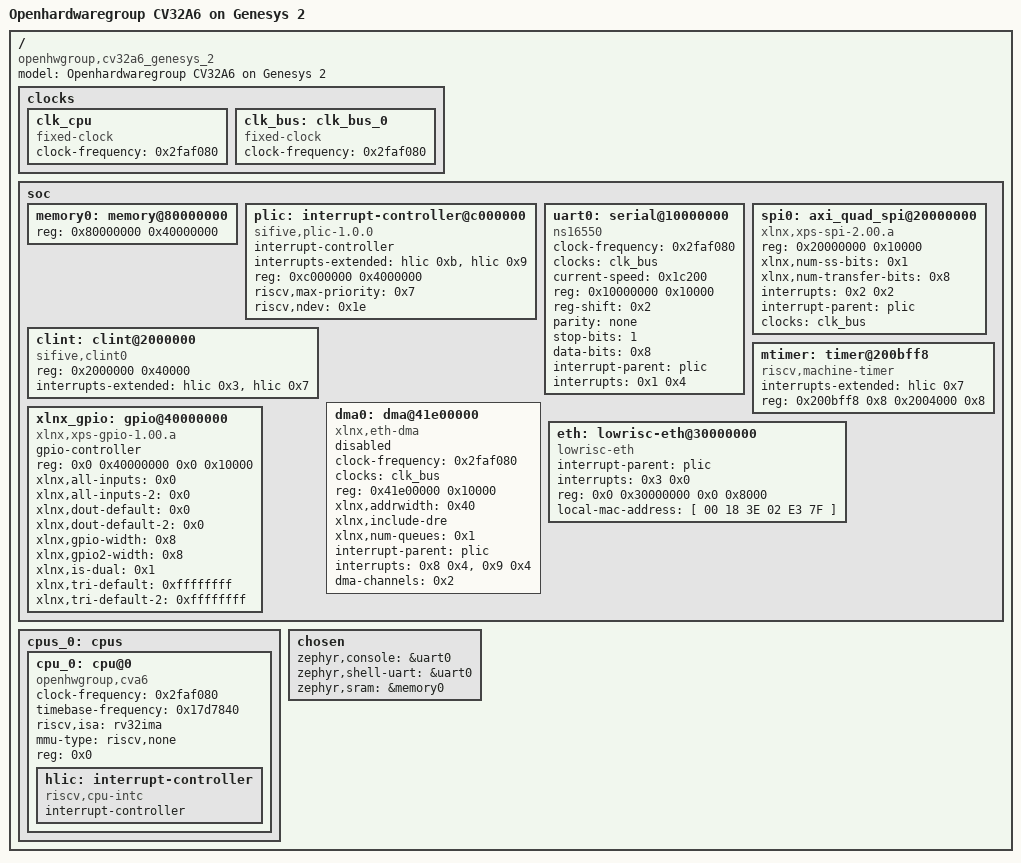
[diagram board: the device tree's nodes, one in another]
/dts-v1/;

/* node '/' defined in zephyr/dts/riscv/openhwgroup/cva6.dtsi:11 */
/ {
	#address-cells = < 0x1 >;                        /* in zephyr/dts/riscv/openhwgroup/cva6.dtsi:12 */
	#size-cells = < 0x1 >;                           /* in zephyr/dts/riscv/openhwgroup/cva6.dtsi:13 */
	model = "Openhardwaregroup CV32A6 on Genesys 2"; /* in zephyr/boards/openhwgroup/cv32a6_genesys_2/cv32a6_genesys_2.dts:11 */
	compatible = "openhwgroup,cv32a6_genesys_2";     /* in zephyr/boards/openhwgroup/cv32a6_genesys_2/cv32a6_genesys_2.dts:12 */

	/* node '/clocks' defined in zephyr/dts/riscv/openhwgroup/cva6.dtsi:15 */
	clocks {

		/* node '/clocks/clk_cpu' defined in zephyr/dts/riscv/openhwgroup/cva6.dtsi:16 */
		clk_cpu {
			#clock-cells = < 0x0 >;          /* in zephyr/dts/riscv/openhwgroup/cva6.dtsi:17 */
			clock-frequency = < 0x2faf080 >; /* in zephyr/dts/riscv/openhwgroup/cva6.dtsi:18 */
			compatible = "fixed-clock";      /* in zephyr/dts/riscv/openhwgroup/cva6.dtsi:19 */
		};

		/* node '/clocks/clk_bus_0' defined in zephyr/dts/riscv/openhwgroup/cva6.dtsi:22 */
		clk_bus: clk_bus_0 {
			#clock-cells = < 0x0 >;          /* in zephyr/dts/riscv/openhwgroup/cva6.dtsi:23 */
			clock-frequency = < 0x2faf080 >; /* in zephyr/dts/riscv/openhwgroup/cva6.dtsi:24 */
			compatible = "fixed-clock";      /* in zephyr/dts/riscv/openhwgroup/cva6.dtsi:25 */
			phandle = < 0x2 >;               /* in zephyr/dts/riscv/openhwgroup/cva6.dtsi:57 */
		};
	};

	/* node '/soc' defined in zephyr/dts/riscv/openhwgroup/cva6.dtsi:29 */
	soc {
		#address-cells = < 0x1 >; /* in zephyr/dts/riscv/openhwgroup/cva6.dtsi:30 */
		#size-cells = < 0x1 >;    /* in zephyr/dts/riscv/openhwgroup/cva6.dtsi:31 */
		ranges;                   /* in zephyr/dts/riscv/openhwgroup/cva6.dtsi:32 */

		/* node '/soc/memory@80000000' defined in zephyr/dts/riscv/openhwgroup/cva6.dtsi:35 */
		memory0: memory@80000000 {
			device_type = "memory";          /* in zephyr/dts/riscv/openhwgroup/cva6.dtsi:36 */
			reg = < 0x80000000 0x40000000 >; /* in zephyr/dts/riscv/openhwgroup/cva6.dtsi:37 */
			status = "okay";                 /* in zephyr/dts/riscv/openhwgroup/cva6.dtsi:38 */
		};

		/* node '/soc/interrupt-controller@c000000' defined in zephyr/dts/riscv/openhwgroup/cva6.dtsi:42 */
		plic: interrupt-controller@c000000 {
			compatible = "sifive,plic-1.0.0";              /* in zephyr/dts/riscv/openhwgroup/cva6.dtsi:43 */
			#address-cells = < 0x0 >;                      /* in zephyr/dts/riscv/openhwgroup/cva6.dtsi:44 */
			#interrupt-cells = < 0x2 >;                    /* in zephyr/dts/riscv/openhwgroup/cva6.dtsi:45 */
			interrupt-controller;                          /* in zephyr/dts/riscv/openhwgroup/cva6.dtsi:46 */
			interrupts-extended = < &hlic 0xb &hlic 0x9 >; /* in zephyr/dts/riscv/openhwgroup/cva6.dtsi:47 */
			reg = < 0xc000000 0x4000000 >;                 /* in zephyr/dts/riscv/openhwgroup/cva6.dtsi:48 */
			riscv,max-priority = < 0x7 >;                  /* in zephyr/dts/riscv/openhwgroup/cva6.dtsi:49 */
			riscv,ndev = < 0x1e >;                         /* in zephyr/dts/riscv/openhwgroup/cva6.dtsi:50 */
			status = "okay";                               /* in zephyr/dts/riscv/openhwgroup/cva6.dtsi:51 */
			phandle = < 0x3 >;                             /* in zephyr/dts/riscv/openhwgroup/cva6.dtsi:66 */
		};

		/* node '/soc/serial@10000000' defined in zephyr/dts/riscv/openhwgroup/cva6.dtsi:55 */
		uart0: serial@10000000 {
			clock-frequency = < 0x2faf080 >; /* in zephyr/dts/riscv/openhwgroup/cva6.dtsi:56 */
			clocks = < &clk_bus >;           /* in zephyr/dts/riscv/openhwgroup/cva6.dtsi:57 */
			compatible = "ns16550";          /* in zephyr/dts/riscv/openhwgroup/cva6.dtsi:58 */
			current-speed = < 0x1c200 >;     /* in zephyr/dts/riscv/openhwgroup/cva6.dtsi:59 */
			device_type = "serial";          /* in zephyr/dts/riscv/openhwgroup/cva6.dtsi:60 */
			reg = < 0x10000000 0x10000 >;    /* in zephyr/dts/riscv/openhwgroup/cva6.dtsi:61 */
			reg-shift = < 0x2 >;             /* in zephyr/dts/riscv/openhwgroup/cva6.dtsi:62 */
			parity = "none";                 /* in zephyr/dts/riscv/openhwgroup/cva6.dtsi:63 */
			stop-bits = "1";                 /* in zephyr/dts/riscv/openhwgroup/cva6.dtsi:64 */
			data-bits = < 0x8 >;             /* in zephyr/dts/riscv/openhwgroup/cva6.dtsi:65 */
			interrupt-parent = < &plic >;    /* in zephyr/dts/riscv/openhwgroup/cva6.dtsi:66 */
			interrupts = < 0x1 0x4 >;        /* in zephyr/dts/riscv/openhwgroup/cva6.dtsi:67 */
			status = "okay";                 /* in zephyr/boards/openhwgroup/cv32a6_genesys_2/cv32a6_genesys_2.dts:22 */
		};

		/* node '/soc/axi_quad_spi@20000000' defined in zephyr/dts/riscv/openhwgroup/cva6.dtsi:72 */
		spi0: axi_quad_spi@20000000 {
			#address-cells = < 0x1 >;           /* in zephyr/dts/riscv/openhwgroup/cva6.dtsi:73 */
			#size-cells = < 0x0 >;              /* in zephyr/dts/riscv/openhwgroup/cva6.dtsi:74 */
			compatible = "xlnx,xps-spi-2.00.a"; /* in zephyr/dts/riscv/openhwgroup/cva6.dtsi:75 */
			reg = < 0x20000000 0x10000 >;       /* in zephyr/dts/riscv/openhwgroup/cva6.dtsi:76 */
			xlnx,num-ss-bits = < 0x1 >;         /* in zephyr/dts/riscv/openhwgroup/cva6.dtsi:77 */
			xlnx,num-transfer-bits = < 0x8 >;   /* in zephyr/dts/riscv/openhwgroup/cva6.dtsi:78 */
			interrupts = < 0x2 0x2 >;           /* in zephyr/dts/riscv/openhwgroup/cva6.dtsi:79 */
			interrupt-parent = < &plic >;       /* in zephyr/dts/riscv/openhwgroup/cva6.dtsi:80 */
			clocks = < &clk_bus >;              /* in zephyr/dts/riscv/openhwgroup/cva6.dtsi:81 */
			status = "okay";                    /* in zephyr/boards/openhwgroup/cv32a6_genesys_2/cv32a6_genesys_2.dts:26 */
		};

		/* node '/soc/clint@2000000' defined in zephyr/dts/riscv/openhwgroup/cva6.dtsi:88 */
		clint: clint@2000000 {
			compatible = "sifive,clint0";                  /* in zephyr/dts/riscv/openhwgroup/cva6.dtsi:89 */
			reg = < 0x2000000 0x40000 >;                   /* in zephyr/dts/riscv/openhwgroup/cva6.dtsi:90 */
			interrupts-extended = < &hlic 0x3 &hlic 0x7 >; /* in zephyr/dts/riscv/openhwgroup/cva6.dtsi:91 */
			status = "okay";                               /* in zephyr/boards/openhwgroup/cv32a6_genesys_2/cv32a6_genesys_2.dts:30 */
		};

		/* node '/soc/timer@200bff8' defined in zephyr/dts/riscv/openhwgroup/cva6.dtsi:95 */
		mtimer: timer@200bff8 {
			compatible = "riscv,machine-timer";    /* in zephyr/dts/riscv/openhwgroup/cva6.dtsi:96 */
			interrupts-extended = < &hlic 0x7 >;   /* in zephyr/dts/riscv/openhwgroup/cva6.dtsi:97 */
			reg = < 0x200bff8 0x8 0x2004000 0x8 >; /* in zephyr/dts/riscv/openhwgroup/cva6.dtsi:98 */
			reg-names = "mtime",
			            "mtimecmp";                /* in zephyr/dts/riscv/openhwgroup/cva6.dtsi:99 */
			status = "okay";                       /* in zephyr/boards/openhwgroup/cv32a6_genesys_2/cv32a6_genesys_2.dts:34 */
		};

		/* node '/soc/dma@41e00000' defined in zephyr/dts/riscv/openhwgroup/cva6.dtsi:108 */
		dma0: dma@41e00000 {
			#dma-cells = < 0x1 >;            /* in zephyr/dts/riscv/openhwgroup/cva6.dtsi:109 */
			clock-frequency = < 0x2faf080 >; /* in zephyr/dts/riscv/openhwgroup/cva6.dtsi:110 */
			clock-names = "s_axi_lite_aclk"; /* in zephyr/dts/riscv/openhwgroup/cva6.dtsi:111 */
			clocks = < &clk_bus >;           /* in zephyr/dts/riscv/openhwgroup/cva6.dtsi:112 */
			compatible = "xlnx,eth-dma";     /* in zephyr/dts/riscv/openhwgroup/cva6.dtsi:113 */
			reg = < 0x41e00000 0x10000 >;    /* in zephyr/dts/riscv/openhwgroup/cva6.dtsi:114 */
			xlnx,addrwidth = < 0x40 >;       /* in zephyr/dts/riscv/openhwgroup/cva6.dtsi:115 */
			xlnx,include-dre;                /* in zephyr/dts/riscv/openhwgroup/cva6.dtsi:116 */
			xlnx,num-queues = < 0x1 >;       /* in zephyr/dts/riscv/openhwgroup/cva6.dtsi:117 */
			interrupt-parent = < &plic >;    /* in zephyr/dts/riscv/openhwgroup/cva6.dtsi:118 */
			interrupts = < 0x8 0x4 >,
			             < 0x9 0x4 >;        /* in zephyr/dts/riscv/openhwgroup/cva6.dtsi:121 */
			dma-channels = < 0x2 >;          /* in zephyr/dts/riscv/openhwgroup/cva6.dtsi:123 */
			status = "disabled";             /* in zephyr/dts/riscv/openhwgroup/cva6.dtsi:124 */
		};

		/* node '/soc/lowrisc-eth@30000000' defined in zephyr/dts/riscv/openhwgroup/cva6.dtsi:131 */
		eth: lowrisc-eth@30000000 {
			compatible = "lowrisc-eth";                /* in zephyr/dts/riscv/openhwgroup/cva6.dtsi:132 */
			device_type = "network";                   /* in zephyr/dts/riscv/openhwgroup/cva6.dtsi:133 */
			interrupt-parent = < &plic >;              /* in zephyr/dts/riscv/openhwgroup/cva6.dtsi:134 */
			interrupts = < 0x3 0x0 >;                  /* in zephyr/dts/riscv/openhwgroup/cva6.dtsi:135 */
			reg = < 0x0 0x30000000 0x0 0x8000 >;       /* in zephyr/dts/riscv/openhwgroup/cva6.dtsi:136 */
			local-mac-address = [ 00 18 3E 02 E3 7F ]; /* in zephyr/boards/openhwgroup/cv32a6_genesys_2/cv32a6_genesys_2.dts:38 */
			status = "okay";                           /* in zephyr/boards/openhwgroup/cv32a6_genesys_2/cv32a6_genesys_2.dts:39 */
		};

		/* node '/soc/gpio@40000000' defined in zephyr/dts/riscv/openhwgroup/cva6.dtsi:141 */
		xlnx_gpio: gpio@40000000 {
			#gpio-cells = < 0x2 >;                /* in zephyr/dts/riscv/openhwgroup/cva6.dtsi:142 */
			compatible = "xlnx,xps-gpio-1.00.a";  /* in zephyr/dts/riscv/openhwgroup/cva6.dtsi:143 */
			gpio-controller;                      /* in zephyr/dts/riscv/openhwgroup/cva6.dtsi:144 */
			reg = < 0x0 0x40000000 0x0 0x10000 >; /* in zephyr/dts/riscv/openhwgroup/cva6.dtsi:145 */
			xlnx,all-inputs = < 0x0 >;            /* in zephyr/dts/riscv/openhwgroup/cva6.dtsi:146 */
			xlnx,all-inputs-2 = < 0x0 >;          /* in zephyr/dts/riscv/openhwgroup/cva6.dtsi:147 */
			xlnx,dout-default = < 0x0 >;          /* in zephyr/dts/riscv/openhwgroup/cva6.dtsi:148 */
			xlnx,dout-default-2 = < 0x0 >;        /* in zephyr/dts/riscv/openhwgroup/cva6.dtsi:149 */
			xlnx,gpio-width = < 0x8 >;            /* in zephyr/dts/riscv/openhwgroup/cva6.dtsi:150 */
			xlnx,gpio2-width = < 0x8 >;           /* in zephyr/dts/riscv/openhwgroup/cva6.dtsi:151 */
			xlnx,is-dual = < 0x1 >;               /* in zephyr/dts/riscv/openhwgroup/cva6.dtsi:152 */
			xlnx,tri-default = < 0xffffffff >;    /* in zephyr/dts/riscv/openhwgroup/cva6.dtsi:153 */
			xlnx,tri-default-2 = < 0xffffffff >;  /* in zephyr/dts/riscv/openhwgroup/cva6.dtsi:154 */
			status = "okay";                      /* in zephyr/boards/openhwgroup/cv32a6_genesys_2/cv32a6_genesys_2.dts:43 */
		};
	};

	/* node '/cpus' defined in zephyr/dts/riscv/openhwgroup/cv32a6.dtsi:16 */
	cpus_0: cpus {
		#address-cells = < 0x1 >; /* in zephyr/dts/riscv/openhwgroup/cv32a6.dtsi:17 */
		#size-cells = < 0x0 >;    /* in zephyr/dts/riscv/openhwgroup/cv32a6.dtsi:18 */

		/* node '/cpus/cpu@0' defined in zephyr/dts/riscv/openhwgroup/cv32a6.dtsi:20 */
		cpu_0: cpu@0 {
			clock-frequency = < 0x2faf080 >;    /* in zephyr/dts/riscv/openhwgroup/cv32a6.dtsi:21 */
			timebase-frequency = < 0x17d7840 >; /* in zephyr/dts/riscv/openhwgroup/cv32a6.dtsi:22 */
			device_type = "cpu";                /* in zephyr/dts/riscv/openhwgroup/cv32a6.dtsi:23 */
			compatible = "openhwgroup,cva6";    /* in zephyr/dts/riscv/openhwgroup/cv32a6.dtsi:24 */
			riscv,isa = "rv32ima";              /* in zephyr/dts/riscv/openhwgroup/cv32a6.dtsi:25 */
			mmu-type = "riscv,none";            /* in zephyr/dts/riscv/openhwgroup/cv32a6.dtsi:27 */
			reg = < 0x0 >;                      /* in zephyr/dts/riscv/openhwgroup/cv32a6.dtsi:28 */
			status = "okay";                    /* in zephyr/dts/riscv/openhwgroup/cv32a6.dtsi:30 */

			/* node '/cpus/cpu@0/interrupt-controller' defined in zephyr/dts/riscv/openhwgroup/cv32a6.dtsi:32 */
			hlic: interrupt-controller {
				#interrupt-cells = < 0x1 >;    /* in zephyr/dts/riscv/openhwgroup/cv32a6.dtsi:33 */
				interrupt-controller;          /* in zephyr/dts/riscv/openhwgroup/cv32a6.dtsi:34 */
				compatible = "riscv,cpu-intc"; /* in zephyr/dts/riscv/openhwgroup/cv32a6.dtsi:35 */
				status = "okay";               /* in zephyr/dts/riscv/openhwgroup/cv32a6.dtsi:36 */
				phandle = < 0x1 >;             /* in zephyr/dts/riscv/openhwgroup/cva6.dtsi:47 */
			};
		};
	};

	/* node '/chosen' defined in zephyr/boards/openhwgroup/cv32a6_genesys_2/cv32a6_genesys_2.dts:14 */
	chosen {
		zephyr,console = &uart0;    /* in zephyr/boards/openhwgroup/cv32a6_genesys_2/cv32a6_genesys_2.dts:15 */
		zephyr,shell-uart = &uart0; /* in zephyr/boards/openhwgroup/cv32a6_genesys_2/cv32a6_genesys_2.dts:16 */
		zephyr,sram = &memory0;     /* in zephyr/boards/openhwgroup/cv32a6_genesys_2/cv32a6_genesys_2.dts:17 */
	};
};
